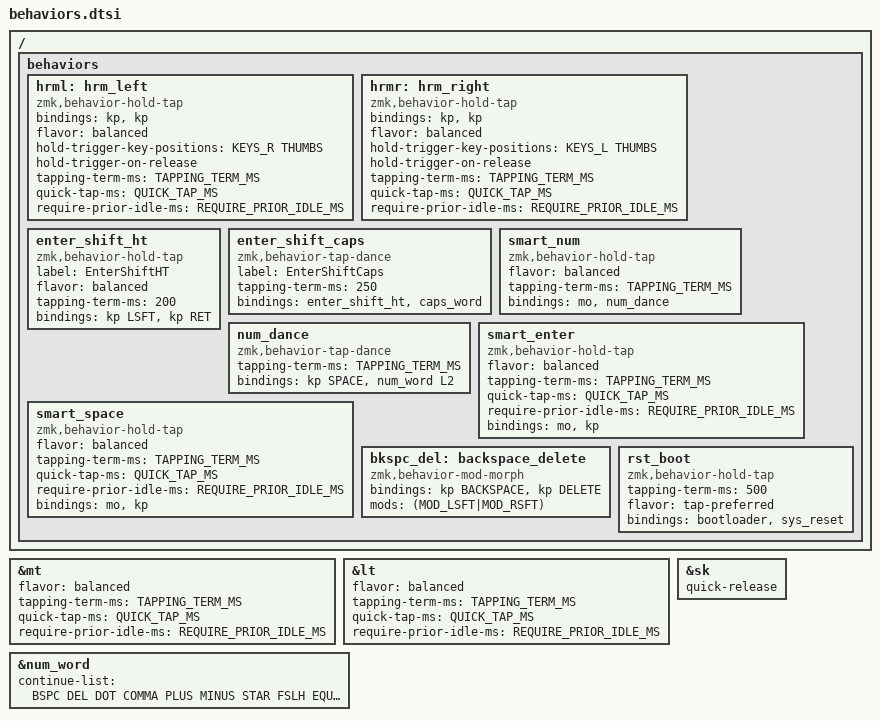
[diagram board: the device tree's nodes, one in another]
// ZMK Behaviors Configuration
&mt {
  flavor = "balanced";
  tapping-term-ms = <TAPPING_TERM_MS>;
  quick-tap-ms = <QUICK_TAP_MS>;
  require-prior-idle-ms = <REQUIRE_PRIOR_IDLE_MS>;
};

&lt {
  flavor = "balanced";
  tapping-term-ms = <TAPPING_TERM_MS>;
  quick-tap-ms = <QUICK_TAP_MS>;
  require-prior-idle-ms = <REQUIRE_PRIOR_IDLE_MS>;
};

&sk {
  quick-release;
};

// From: https://github.com/urob/zmk-config/
// num-word, requires PR https://github.com/zmkfirmware/zmk/pull/1451
// Adds arrows and shift to smart layer for more comfortable navigation/selection moves
&num_word {
  continue-list = <BSPC DEL DOT COMMA PLUS MINUS STAR FSLH EQUAL RSHFT LEFT RIGHT UP DOWN>;
};

/ {
  behaviors {
    /*
    Home Row Mods

    - tap: &kp <PARAM_2>
    - hold: &kp <PARAM_1>

    Example: &hrml LCMD T
    */
    /omit-if-no-ref/ hrml: hrm_left {
      bindings = <&kp>, <&kp>;
      compatible = "zmk,behavior-hold-tap";
      flavor = "balanced";
      hold-trigger-key-positions = <KEYS_R THUMBS>;
      hold-trigger-on-release;
      tapping-term-ms = <TAPPING_TERM_MS>;
      quick-tap-ms = <QUICK_TAP_MS>;
      require-prior-idle-ms = <REQUIRE_PRIOR_IDLE_MS>;
      #binding-cells = <2>;
    };

    /omit-if-no-ref/ hrmr: hrm_right {
      bindings = <&kp>, <&kp>;
      compatible = "zmk,behavior-hold-tap";
      flavor = "balanced";
      hold-trigger-key-positions = <KEYS_L THUMBS>;
      hold-trigger-on-release;
      tapping-term-ms = <TAPPING_TERM_MS>;
      quick-tap-ms = <QUICK_TAP_MS>;
      require-prior-idle-ms = <REQUIRE_PRIOR_IDLE_MS>;
      #binding-cells = <2>;
    };

/omit-if-no-ref/ enter_shift_ht {
  compatible = "zmk,behavior-hold-tap";
  label = "EnterShiftHT";
  flavor = "balanced";
  tapping-term-ms = <200>;
  bindings = <&kp LSFT>, <&kp RET>;
  #binding-cells = <0>;
};
/omit-if-no-ref/ enter_shift_caps {
  compatible = "zmk,behavior-tap-dance";
  label = "EnterShiftCaps";
  tapping-term-ms = <250>;     // controls double-tap detection window
  bindings = <&enter_shift_ht>, <&caps_word>;
  #binding-cells = <0>;
};


    /*
    - tap: num-word
    - hold: &mo layer

    From: https://github.com/urob/zmk-config/
    */
    /omit-if-no-ref/ smart_num: smart_num {
      compatible = "zmk,behavior-hold-tap";
      flavor = "balanced";
      tapping-term-ms = <TAPPING_TERM_MS>;
      bindings = <&mo>, <&num_dance>;
      #binding-cells = <2>;
    };

    /*
    - tap: &sl L2
    - tap x 2: &num_word

    From: https://github.com/urob/zmk-config/
    */
    /omit-if-no-ref/ num_dance: num_dance {
      compatible = "zmk,behavior-tap-dance";
      tapping-term-ms = <TAPPING_TERM_MS>;
      bindings = <&kp SPACE>, <&num_word L2>;
      #binding-cells = <0>;
    };
    /omit-if-no-ref/ smart_enter: smart_enter {
      compatible = "zmk,behavior-hold-tap";
      flavor = "balanced";
      tapping-term-ms = <TAPPING_TERM_MS>;
      quick-tap-ms = <QUICK_TAP_MS>;
      require-prior-idle-ms = <REQUIRE_PRIOR_IDLE_MS>;
      bindings = <&mo>, <&kp>;
      #binding-cells = <2>;
    };
      /omit-if-no-ref/ smart_space: smart_space {
      compatible = "zmk,behavior-hold-tap";
      flavor = "balanced";
      tapping-term-ms = <TAPPING_TERM_MS>;
      quick-tap-ms = <QUICK_TAP_MS>;
      require-prior-idle-ms = <REQUIRE_PRIOR_IDLE_MS>;
      bindings = <&mo>, <&kp>;
      #binding-cells = <2>;
    };

   


    /*
    - tap: backspace
    - hold: repeat backspace
    - shift + tap: delete
    - shift + hold: repeat delete

    From: https://zmk.dev/docs/behaviors/mod-morph#advanced-configuration
    */
    /omit-if-no-ref/ bkspc_del: backspace_delete {
      compatible = "zmk,behavior-mod-morph";
      bindings = <&kp BACKSPACE>, <&kp DELETE>;
      mods = <(MOD_LSFT|MOD_RSFT)>;
      #binding-cells = <0>;
    };

    /*
    - tap: reset keyboard
    - hold: enter bootloader mode
    */
    /omit-if-no-ref/ rst_boot: rst_boot {
        compatible = "zmk,behavior-hold-tap";
        #binding-cells = <2>;
        tapping-term-ms = <500>;
        flavor = "tap-preferred";
        bindings = <&bootloader>, <&sys_reset>;
    };
  };
};
